# va416xx register map
Vendor: VORAGO TECHNOLOGIES; Series: M4; File version: 1.3
CPU: CM4 r0p1, little endian, no MPU, FPU, 3 interrupt priority bits
Registers are 32-bit, read-write, reset 0x0 unless marked. A register's access mark holds for its fields unless they carry their own. Offsets are from the block's base; [hi:lo] are bit positions; {n}, {i} and the like mark numbered series.

## IRQ_ROUTER — Interrupt Router Peripheral
Base 0x40002000
{0x0+4i} DMASEL{i} reset 0x7F (i=0..3) — Interrupt select for DMA channel {i}
  [6:0] DMASEL — DMA trigger source selection value
0x10 DMATTSEL — Trigger select for the DMA channels
  [3:0] DMATTSEL — DMA trigger type selection value
0x14 ADCSEL reset 0x1F — Interrupt select for ADC
  [4:0] ADCSEL — ADC trigger source selection value
0x18 DACSEL0 reset 0x1F — Interrupt select for DAC0
  [4:0] DACSEL — DAC trigger source selection value
0x1C DACSEL1 reset 0x1F — Interrupt select for DAC1
  [4:0] DACSEL — DAC trigger source selection value
{0x20+4i} IRQ_OUT{i} ro (i=0..4) — DEBUG IRQ_OUT[{32i+31}:{32i}]
  [31:0] IRQ_OUT{i} — IRQ_OUT[{32i+31}:{32i}]
0x34 IRQ_OUT5 ro — DEBUG IRQ_OUT[179:160]
  [19:0] IRQ_OUT5 — IRQ_OUT[179:160]
0xFFC PERID ro reset 0x28107E9 — Peripheral ID Register

## WATCH_DOG — Watchdog Block Peripheral
Base 0x40021000
0x00 WDOGLOAD reset 0xFFFFFFFF — Counter Start Value
  [31:0] CNT — Count to load
0x04 WDOGVALUE ro reset 0xFFFFFFFF — Down Counter Value
  [31:0] CNT — Actual Count
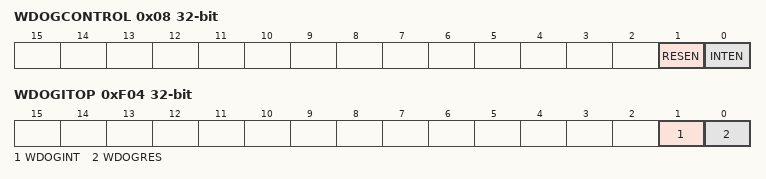
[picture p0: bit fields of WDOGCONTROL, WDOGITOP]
0x08 WDOGCONTROL — Enable for block reset and interrupt
  [1] RESEN — Enable watchdog reset output
  [0] INTEN — Enable watchdog interrupt
0x0C WDOGINTCLR — A write of any value clears the WDT module interrupt, and reloads the counter from the value in the WDOGLOAD Register
  [31:0] CLEAR — Write any value to clear interrupt
0x10 WDOGRIS ro — Raw interrupt status
  [0] INTERRUPT — Interrupt Status
0x14 WDOGMIS ro — Interrupt status
  [0] INTERRUPT — Masked Interrupt Status
0xC00 WDOGLOCK — Lock
  [31:0] REG_WR_EN — Register write enable status
0xF00 WDOGITCR — Integration test control
  [0] TEST_MODE_EN — Enable test mode of WDOGINT and WDOGRES
0xF04 WDOGITOP — Integration test output set
  [1] WDOGINT — Set output value
  [0] WDOGRES — Set output value
0xFE0 WDOGPERIPHID0 ro reset 0x24 — Peripheral ID
  [7:0] PERIPHID
0xFE4 WDOGPERIPHID1 ro reset 0xB8 — Peripheral ID
  [7:0] PERIPHID
0xFE8 WDOGPERIPHID2 ro reset 0x1B — Peripheral ID
  [7:0] PERIPHID
0xFEC WDOGPERIPHID3 ro — Peripheral ID
  [7:0] PERIPHID
0xFF0 WDOGPCELLID0 ro reset 0xD — PrimeCell ID
  [7:0] PCELLID — Prime Cell ID
0xFF4 WDOGPCELLID1 ro reset 0xF0 — PrimeCell ID
  [7:0] PCELLID — Prime Cell ID
0xFF8 WDOGPCELLID2 ro reset 0x5 — PrimeCell ID
  [7:0] PCELLID — Prime Cell ID
0xFFC WDOGPCELLID3 ro reset 0xB1 — PrimeCell ID
  [7:0] PCELLID — Prime Cell ID

## TRNG — True Random Number Generator
Base 0x40027000
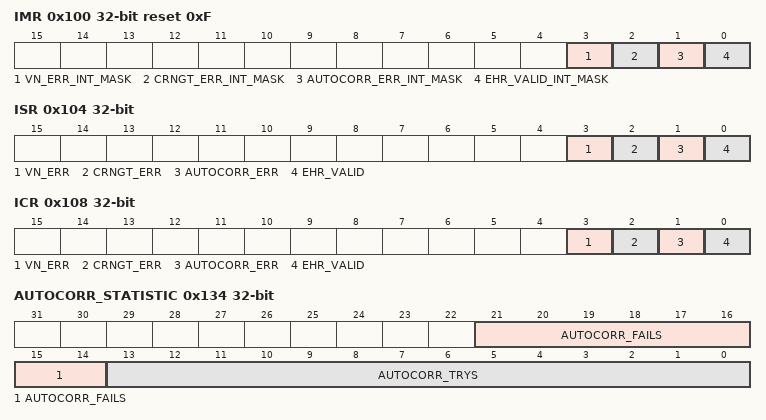
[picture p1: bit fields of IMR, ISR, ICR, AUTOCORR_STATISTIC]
0x100 IMR reset 0xF — Interrupt Mask Register
  [3] VN_ERR_INT_MASK — Mask the Von Neumann error
  [2] CRNGT_ERR_INT_MASK — Mask the CRNGT error
  [1] AUTOCORR_ERR_INT_MASK — Mask the Autocorrelation error
  [0] EHR_VALID_INT_MASK — Mask when the TRNG has collected 192 bits
0x104 ISR ro — Interrupt Status Register
  [3] VN_ERR — Indicates a Von Neumann error
  [2] CRNGT_ERR — Indicates a Continuous Random Number Generation Testing (CRNGT) error
  [1] AUTOCORR_ERR — Indicates that the Autocorrelation test failed four times in a row
  [0] EHR_VALID — 192 bits have been collected in the TRNG
0x108 ICR — Interrupt Clear Register
  [3] VN_ERR — Clears a Von Neumann error
  [2] CRNGT_ERR — Clear a Continuous Random Number Generation Testing (CRNGT) error
  [1] AUTOCORR_ERR — Software cannot clear this bit. Only a TRNG reset can clear this bit
  [0] EHR_VALID — Set to 1 after the EHR_DATA[0,1,2,3,4,5] registers have been read
0x10C CONFIG — Configuration Register
  [1:0] RND_SRC_SEL — Selects the number of inverters (out of four possible selections) in the ring oscillator
0x110 VALID ro
  [0] EHR_VALID — Indicates that the collection of bits in the TRNG is complete
{0x114+4i} EHR_DATA{i} ro (i=0..5) — Entropy Holding Register Data Register
  [31:0] EHR_DATA — 32 Bits of Entropy Holding Register
0x12C RND_SOURCE_ENABLE — Random Source Enable Register
  [0] RND_SRC_EN — The entropy source, ring oscillator, is enabled
0x130 SAMPLE_CNT1 reset 0xFFFF — Section TBD
  [31:0] SAMPLE_CNTR1 — Sets the number of clk cycles between two consecutive ring oscillator samples
0x134 AUTOCORR_STATISTIC — Auto-correlator Statistic Register
  [21:14] AUTOCORR_FAILS — Count each time an autocorrelation test fails
  [13:0] AUTOCORR_TRYS — Count each time an autocorrelation test starts
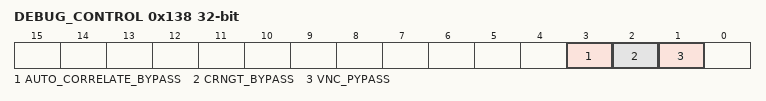
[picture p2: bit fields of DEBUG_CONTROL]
0x138 DEBUG_CONTROL — Section TBD
  [3] AUTO_CORRELATE_BYPASS — The autocorrelation test in the TRNG module is bypassed
  [2] CRNGT_BYPASS — The CRNGT test in the TRNG is bypassed
  [1] VNC_PYPASS — The Von Neumann balancer is bypassed
0x140 SW_RESET — Reset Register
  [0] SW_RESET — Writing 1 to this register causes an internal TRNG reset
0x1B8 BUSY ro
  [0] BUSY — Reflects the status of the rng_busy signal
0x1BC RST_BITS_COUNTER — Reset Bits Counter Register
  [0] RST_BITS_COUNTER — Writing any value to this bit resets the bits counter and TRNG valid registers
{0x1E0+4i} BIST_CNTR{i} ro (i=0..2) — BIST Counter Register
  [21:0] ROSC_CNTR_VAL — Returns the results of the TRNG BIST counter
